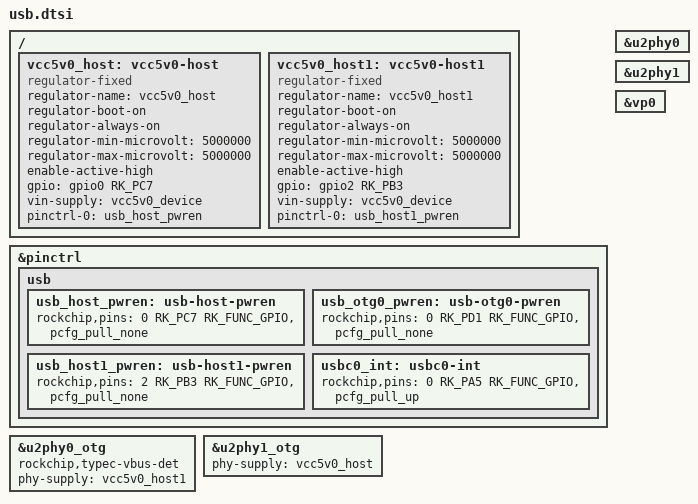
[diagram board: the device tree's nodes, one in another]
/ {
	vcc5v0_host: vcc5v0-host {
		compatible = "regulator-fixed";
		regulator-name = "vcc5v0_host";
		regulator-boot-on;
		regulator-always-on;
		regulator-min-microvolt = <5000000>;
		regulator-max-microvolt = <5000000>;
		enable-active-high;
		gpio = <&gpio0 RK_PC7 GPIO_ACTIVE_HIGH>;
		vin-supply = <&vcc5v0_device>;
		pinctrl-names = "default";
		pinctrl-0 = <&usb_host_pwren>;
	};

	vcc5v0_host1: vcc5v0-host1 {
		compatible = "regulator-fixed";
		regulator-name = "vcc5v0_host1";
		regulator-boot-on;
		regulator-always-on;
		regulator-min-microvolt = <5000000>;
		regulator-max-microvolt = <5000000>;
		enable-active-high;
		gpio = <&gpio2 RK_PB3 GPIO_ACTIVE_HIGH>;
		vin-supply = <&vcc5v0_device>;
		pinctrl-names = "default";
		pinctrl-0 = <&usb_host1_pwren>;
	};
};

&pinctrl {
	usb {
		usb_host_pwren: usb-host-pwren {
			rockchip,pins = <0 RK_PC7 RK_FUNC_GPIO &pcfg_pull_none>;
		};

		usb_otg0_pwren: usb-otg0-pwren {
			rockchip,pins = <0 RK_PD1 RK_FUNC_GPIO &pcfg_pull_none>;
		};

		usb_host1_pwren: usb-host1-pwren {
			rockchip,pins = <2 RK_PB3 RK_FUNC_GPIO &pcfg_pull_none>;
		};

		usbc0_int: usbc0-int {
			rockchip,pins = <0 RK_PA5 RK_FUNC_GPIO &pcfg_pull_up>;
		};
	};

};

// USB OTG端口配置，启用Type-C VBUS检测
&u2phy0_otg {
	rockchip,typec-vbus-det;
};

&u2phy0 {
	status = "okay";
};

&u2phy1 {
	status = "okay";
};


//cn1
&u2phy0_otg {
	status = "okay";
	phy-supply = <&vcc5v0_host1>;
};

//cn2
&u2phy1_otg {
	status = "okay";
	phy-supply = <&vcc5v0_host>;
};






&vp0 {
	status = "okay";
};

